VERSION ""

NS_ :

BS_:

BU_: BRAKE STEERING THROTTLE FAULT STEERING_CTRL DIAGNOSTICS

BO_ 112 BRAKE_ENABLE: 8 BRAKE
 SG_ brake_enable_magic : 0|16@1+ (1,0) [0|0] "" BRAKE

BO_ 113 BRAKE_DISABLE: 8 BRAKE
 SG_ brake_disable_magic : 0|16@1+ (1,0) [0|0] "" BRAKE

BO_ 114 BRAKE_COMMAND: 8 BRAKE
 SG_ brake_command_magic : 0|16@1+ (1,0) [0|0] "" BRAKE
 SG_ brake_pedal_command : 16|32@1- (1,0) [0|1] "" BRAKE

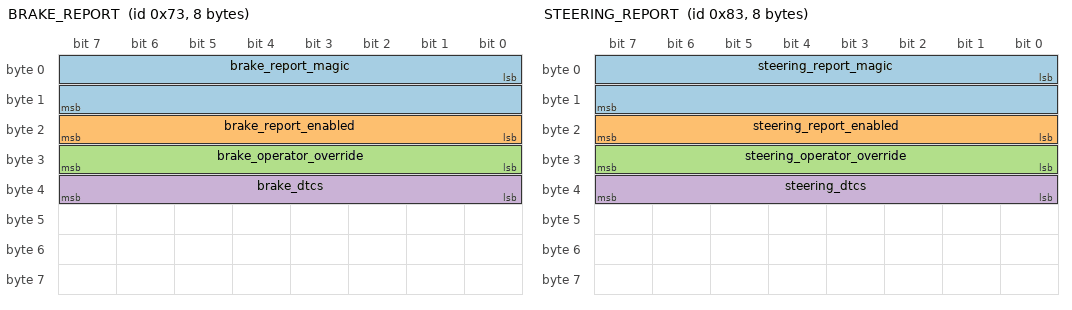
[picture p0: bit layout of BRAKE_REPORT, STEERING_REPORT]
BO_ 115 BRAKE_REPORT: 8 BRAKE
 SG_ brake_report_magic : 0|16@1+ (1,0) [0|0] "" BRAKE
 SG_ brake_report_enabled : 16|8@1+ (1,0) [0|0] "" BRAKE
 SG_ brake_operator_override : 24|8@1+ (1,0) [0|0] "" BRAKE
 SG_ brake_dtcs : 32|8@1+ (1,0) [0|0] "" BRAKE

BO_ 128 STEERING_ENABLE: 8 STEERING
 SG_ steering_enable_magic : 0|16@1+ (1,0) [0|0] "" STEERING

BO_ 129 STEERING_DISABLE: 8 STEERING
 SG_ steering_disable_magic : 0|16@1+ (1,0) [0|0] "" STEERING

BO_ 130 STEERING_TORQUE_COMMAND: 8 STEERING
 SG_ steering_command_magic : 0|16@1+ (1,0) [0|0] "" STEERING
 SG_ steering_torque_command : 16|32@1- (1,0) [-1|1] "" STEERING

BO_ 131 STEERING_REPORT: 8 STEERING
 SG_ steering_report_magic : 0|16@1+ (1,0) [0|0] "" STEERING
 SG_ steering_report_enabled : 16|8@1+ (1,0) [0|0] "" STEERING
 SG_ steering_operator_override : 24|8@1+ (1,0) [0|0] "" STEERING
 SG_ steering_dtcs : 32|8@1+ (1,0) [0|0] "" STEERING

BO_ 144 THROTTLE_ENABLE: 8 THROTTLE
 SG_ throttle_enable_magic : 0|16@1+ (1,0) [0|0] "" THROTTLE

BO_ 145 THROTTLE_DISABLE: 8 THROTTLE
 SG_ throttle_disable_magic : 0|16@1+ (1,0) [0|0] "" THROTTLE

BO_ 146 THROTTLE_COMMAND: 8 THROTTLE
 SG_ throttle_command_magic : 0|16@1+ (1,0) [0|0] "" THROTTLE
 SG_ throttle_pedal_command : 16|32@1- (1,0) [0|1] "" THROTTLE

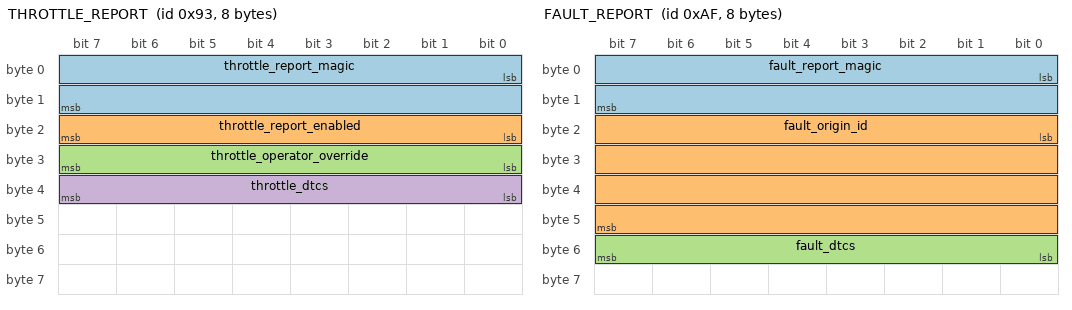
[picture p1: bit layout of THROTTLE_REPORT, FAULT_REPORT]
BO_ 147 THROTTLE_REPORT: 8 THROTTLE
 SG_ throttle_report_magic : 0|16@1+ (1,0) [0|0] "" THROTTLE
 SG_ throttle_report_enabled : 16|8@1+ (1,0) [0|0] "" THROTTLE
 SG_ throttle_operator_override : 24|8@1+ (1,0) [0|0] "" THROTTLE
 SG_ throttle_dtcs : 32|8@1+ (1,0) [0|0] "" THROTTLE

BO_ 175 FAULT_REPORT: 8 FAULT
 SG_ fault_report_magic : 0|16@1+ (1,0) [0|0] "" FAULT
 SG_ fault_origin_id : 16|32@1+ (1,0) [0|0] "" FAULT
 SG_ fault_dtcs : 48|8@1+ (1,0) [0|0] "" FAULT

BO_ 185 STEERING_ANGLE_REPORT: 8 STEERING_CTRL
 SG_ steering_angle_report_flags : 0|8@1+ (1,0) [0|0] "" STEERING_CTRL
 SG_ steering_angle_report_errors : 8|8@1+ (1,0) [0|0] "" STEERING_CTRL

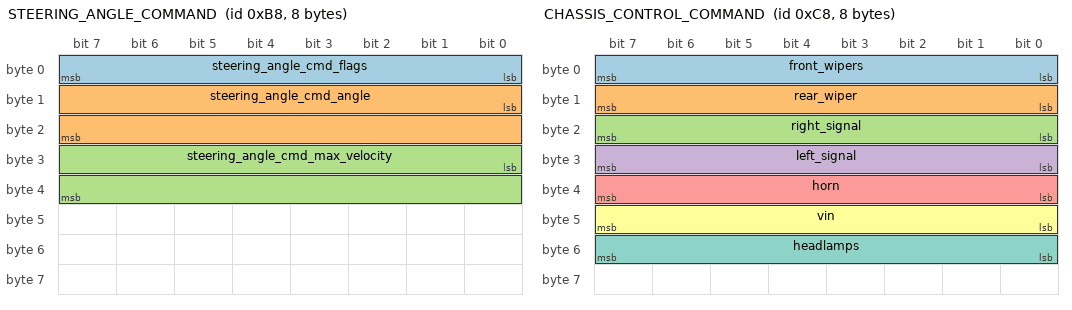
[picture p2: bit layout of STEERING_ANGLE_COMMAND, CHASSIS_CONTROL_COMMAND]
BO_ 184 STEERING_ANGLE_COMMAND: 8 STEERING_CTRL
 SG_ steering_angle_cmd_flags : 0|8@1+ (1,0) [0|0] "" STEERING_CTRL
 SG_ steering_angle_cmd_angle : 8|16@1- (0.1,0) [0|0] "" STEERING_CTRL
 SG_ steering_angle_cmd_max_velocity : 24|16@1- (0.1,0) [0|0] "" STEERING_CTRL

BO_ 200 CHASSIS_CONTROL_COMMAND: 8 DIAGNOSTICS
 SG_ front_wipers : 0|8@1+ (1,0) [0|0] "" DIAGNOSTICS
 SG_ rear_wiper : 8|8@1+ (1,0) [0|0] "" DIAGNOSTICS
 SG_ right_signal : 16|8@1+ (1,0) [0|0] "" DIAGNOSTICS
 SG_ left_signal : 24|8@1+ (1,0) [0|0] "" DIAGNOSTICS
 SG_ horn : 32|8@1+ (1,0) [0|0] "" DIAGNOSTICS
 SG_ vin : 40|8@1+ (1,0) [0|0] "" DIAGNOSTICS
 SG_ headlamps : 48|8@1+ (1,0) [0|0] "" DIAGNOSTICS

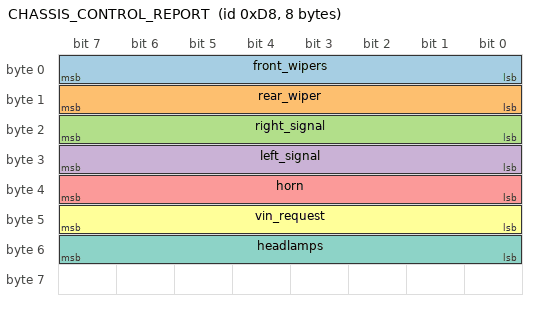
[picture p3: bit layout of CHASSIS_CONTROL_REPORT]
BO_ 216 CHASSIS_CONTROL_REPORT: 8 DIAGNOSTICS
 SG_ front_wipers : 0|8@1+ (1,0) [0|0] "" DIAGNOSTICS
 SG_ rear_wiper : 8|8@1+ (1,0) [0|0] "" DIAGNOSTICS
 SG_ right_signal : 16|8@1+ (1,0) [0|0] "" DIAGNOSTICS
 SG_ left_signal : 24|8@1+ (1,0) [0|0] "" DIAGNOSTICS
 SG_ horn : 32|8@1+ (1,0) [0|0] "" DIAGNOSTICS
 SG_ vin_request : 40|8@1+ (1,0) [0|0] "" DIAGNOSTICS
 SG_ headlamps : 48|8@1+ (1,0) [0|0] "" DIAGNOSTICS

CM_ BU_ BRAKE "The OSCC brake module";
CM_ BU_ STEERING "The OSCC steering module";
CM_ BU_ THROTTLE "The OSCC throttle module";
CM_ BU_ FAULT "The OSCC fault report";
CM_ BU_ STEERING_CTRL "The DriveKit PID Steering Angle Control";

VAL_ 185 steering_angle_report_flags 0 "Enable";
VAL_ 185 steering_angle_report_errors 6 "Command Rejected" 4 "Module Disabled" 2 "Angle Irrational" 1 "Angle Missing" 0 "None";
VAL_ 184 steering_angle_cmd_flags 1 "Enable" 0 "Disable";

VAL_ 200 front_wipers 0 "Do Nothing" 1 "Disable" 2 "Intermittent" 3 "Slow" 4 "Fast";
VAL_ 200 rear_wiper 0 "Do Nothing"  1 "Disable" 2 "Enable";
VAL_ 200 right_signal 0 "Do Nothing" 1 "Disable" 2 "Enable";
VAL_ 200 left_signal 0 "Do Nothing"  1 "Disable" 2 "Enable";
VAL_ 200 horn 0 "Do Nothing" 2 "Enabled";
VAL_ 200 vin 0 "Do Nothing" 2 "Requested";
VAL_ 200 headlamps 0 "Do Nothing" 1 "Disable" 2 "Low" 3 "High";
VAL_ 216 front_wipers 0 "Disabled" 1 "Intermittent" 2 "Slow" 3 "Fast";
VAL_ 216 rear_wiper 0 "Disabled" 1 "Enabled";
VAL_ 216 right_signal 0 "Disabled" 1 "Enabled";
VAL_ 216 left_signal 0 "Disabled" 1 "Enabled";
VAL_ 216 horn 0 "Disabled" 1 "Enabled";
VAL_ 216 vin_request 0 "Disabled" 1 "Enabled";
VAL_ 216 headlamps 0 "Disabled" 1 "Low" 2 "High";

VAL_ 115 brake_dtcs 0 "No communication with brake sensor" 1 "Operator Override: Brake";
VAL_ 131 steering_dtcs 0 "No communication with steering sensor" 1 "Operator Override: Steering";
VAL_ 147 throttle_dtcs 0 "No communication with throttle sensor" 1 "Operator Override: Throttle";
VAL_ 175 fault_dtcs 0 "No communication with sensor" 1 "Operator Override";

VAL_ 112 brake_enable_magic 1372 "Default Magic Number";
VAL_ 113 brake_disable_magic 1372 "Default Magic Number";
VAL_ 114 brake_command_magic 1372 "Default Magic Number";
VAL_ 115 brake_report_magic 1372 "Default Magic Number";
VAL_ 128 steering_enable_magic 1372 "Default Magic Number";
VAL_ 129 steering_disable_magic 1372 "Default Magic Number";
VAL_ 130 steering_command_magic 1372 "Default Magic Number";
VAL_ 131 steering_report_magic 1372 "Default Magic Number";
VAL_ 144 throttle_enable_magic 1372 "Default Magic Number";
VAL_ 145 throttle_disable_magic 1372 "Default Magic Number";
VAL_ 146 throttle_command_magic 1372 "Default Magic Number";
VAL_ 147 throttle_report_magic 1372 "Default Magic Number";
VAL_ 175 fault_report_magic 1372 "Default Magic Number";

SIG_VALTYPE_ 114 brake_pedal_command : 1;
SIG_VALTYPE_ 130 steering_torque_command : 1;
SIG_VALTYPE_ 146 throttle_pedal_command : 1;
